# STM32F767xx register map
File version: 1.0
Registers are 32-bit, read-write, reset 0x0 unless marked. A register's access mark holds for its fields unless they carry their own. Offsets are from the block's base; [hi:lo] are bit positions; {n}, {i} and the like mark numbered series.

## DMA1
Base 0x40026000
Same registers: DMA2 0x40026400
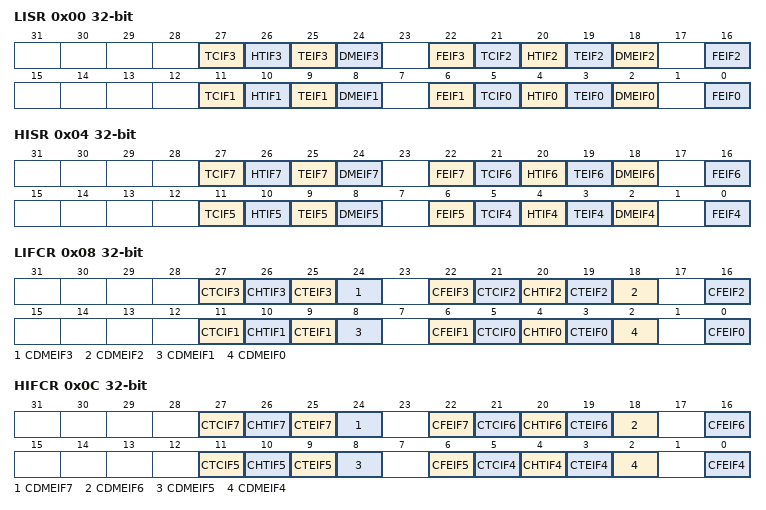
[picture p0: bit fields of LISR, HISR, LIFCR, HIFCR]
0x00 LISR — DMA low interrupt status register
  [27] TCIF3, [26] HTIF3, [25] TEIF3, [24] DMEIF3, [22] FEIF3, [21] TCIF2, [20] HTIF2, [19] TEIF2, [18] DMEIF2, [16] FEIF2, [11] TCIF1, [10] HTIF1, [9] TEIF1, [8] DMEIF1, [6] FEIF1, [5] TCIF0, [4] HTIF0, [3] TEIF0, [2] DMEIF0, [0] FEIF0
0x04 HISR — DMA high interrupt status register
  [27] TCIF7, [26] HTIF7, [25] TEIF7, [24] DMEIF7, [22] FEIF7, [21] TCIF6, [20] HTIF6, [19] TEIF6, [18] DMEIF6, [16] FEIF6, [11] TCIF5, [10] HTIF5, [9] TEIF5, [8] DMEIF5, [6] FEIF5, [5] TCIF4, [4] HTIF4, [3] TEIF4, [2] DMEIF4, [0] FEIF4
0x08 LIFCR — DMA low interrupt flag clear register
  [27] CTCIF3, [26] CHTIF3, [25] CTEIF3, [24] CDMEIF3, [22] CFEIF3, [21] CTCIF2, [20] CHTIF2, [19] CTEIF2, [18] CDMEIF2, [16] CFEIF2, [11] CTCIF1, [10] CHTIF1, [9] CTEIF1, [8] CDMEIF1, [6] CFEIF1, [5] CTCIF0, [4] CHTIF0, [3] CTEIF0, [2] CDMEIF0, [0] CFEIF0
0x0C HIFCR — DMA high interrupt flag clear register
  [27] CTCIF7, [26] CHTIF7, [25] CTEIF7, [24] CDMEIF7, [22] CFEIF7, [21] CTCIF6, [20] CHTIF6, [19] CTEIF6, [18] CDMEIF6, [16] CFEIF6, [11] CTCIF5, [10] CHTIF5, [9] CTEIF5, [8] CDMEIF5, [6] CFEIF5, [5] CTCIF4, [4] CHTIF4, [3] CTEIF4, [2] CDMEIF4, [0] CFEIF4
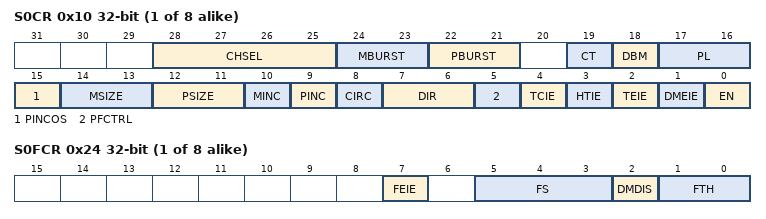
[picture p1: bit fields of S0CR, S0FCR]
{0x10+0x18*i} S{i}CR (i=0..7) — DMA stream x configuration register
  [28:25] CHSEL, [24:23] MBURST, [22:21] PBURST, [19] CT, [18] DBM, [17:16] PL, [15] PINCOS, [14:13] MSIZE, [12:11] PSIZE, [10] MINC, [9] PINC, [8] CIRC, [7:6] DIR, [5] PFCTRL, [4] TCIE, [3] HTIE, [2] TEIE, [1] DMEIE, [0] EN
{0x14+0x18*i} S{i}NDTR (i=0..7) — DMA stream x number of data register
  [15:0] SxNDT
{0x18+0x18*i} S{i}PAR (i=0..7) — DMA stream x peripheral address register
  [31:0] PA — Peripheral Address
{0x1C+0x18*i} S{i}M0AR (i=0..7) — DMA stream x memory 0 address register
  [31:0] M0A — Memory Address
{0x20+0x18*i} S{i}M1AR (i=0..7) — DMA stream x memory 1 address register
  [31:0] M1A — Memory Address
{0x24+0x18*i} S{i}FCR (i=0..7) — DMA stream x FIFO control register
  [7] FEIE, [5:3] FS, [2] DMDIS, [1:0] FTH

## ETH — Ethernet MAC
Base 0x40028000
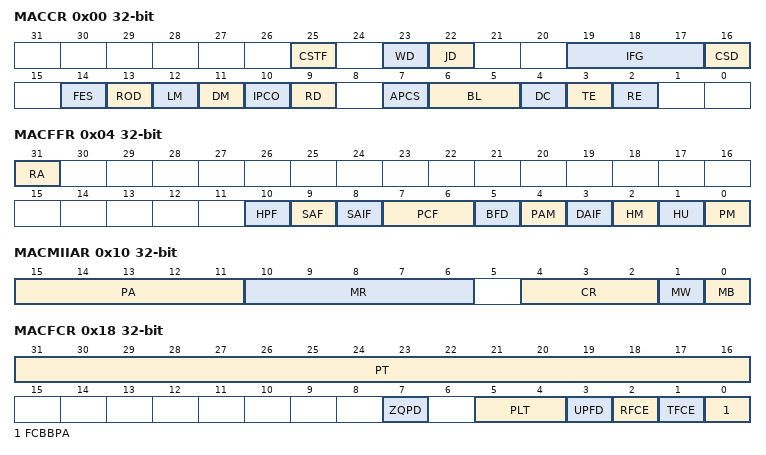
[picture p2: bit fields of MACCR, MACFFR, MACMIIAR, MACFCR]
0x00 MACCR
  [25] CSTF, [23] WD, [22] JD, [19:17] IFG, [16] CSD, [14] FES, [13] ROD, [12] LM, [11] DM, [10] IPCO, [9] RD, [7] APCS, [6:5] BL, [4] DC, [3] TE, [2] RE
0x04 MACFFR
  [31] RA, [10] HPF, [9] SAF, [8] SAIF, [7:6] PCF, [5] BFD, [4] PAM, [3] DAIF, [2] HM, [1] HU, [0] PM
0x08 MACHTHR
  [31:0] HTH
0x0C MACHTLR
  [31:0] HTL
0x10 MACMIIAR
  [15:11] PA, [10:6] MR, [4:2] CR, [1] MW, [0] MB
0x14 MACMIIDR
  [15:0] MD
0x18 MACFCR
  [31:16] PT, [7] ZQPD, [5:4] PLT, [3] UPFD, [2] RFCE, [1] TFCE, [0] FCBBPA
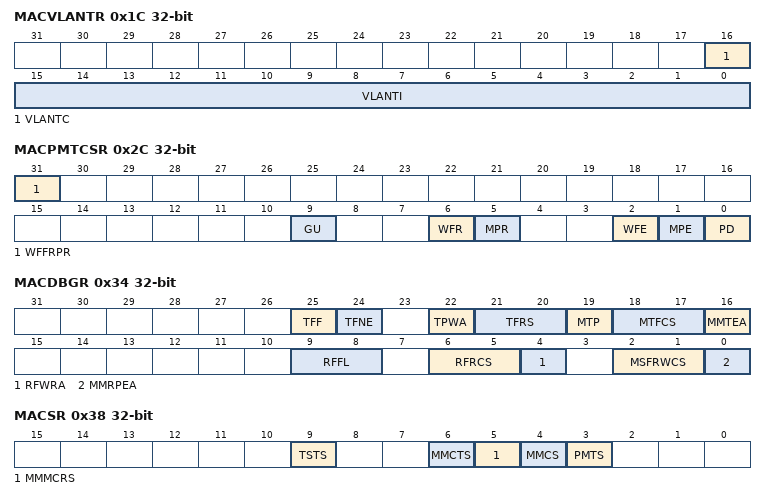
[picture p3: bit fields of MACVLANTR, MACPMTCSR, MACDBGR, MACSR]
0x1C MACVLANTR
  [16] VLANTC, [15:0] VLANTI
0x28 MACRWUFFR
  [31:0] D
0x2C MACPMTCSR
  [31] WFFRPR, [9] GU, [6] WFR, [5] MPR, [2] WFE, [1] MPE, [0] PD
0x34 MACDBGR
  [25] TFF, [24] TFNE, [22] TPWA, [21:20] TFRS, [19] MTP, [18:17] MTFCS, [16] MMTEA, [9:8] RFFL, [6:5] RFRCS, [4] RFWRA, [2:1] MSFRWCS, [0] MMRPEA
0x38 MACSR
  [9] TSTS, [6] MMCTS, [5] MMMCRS, [4] MMCS, [3] PMTS
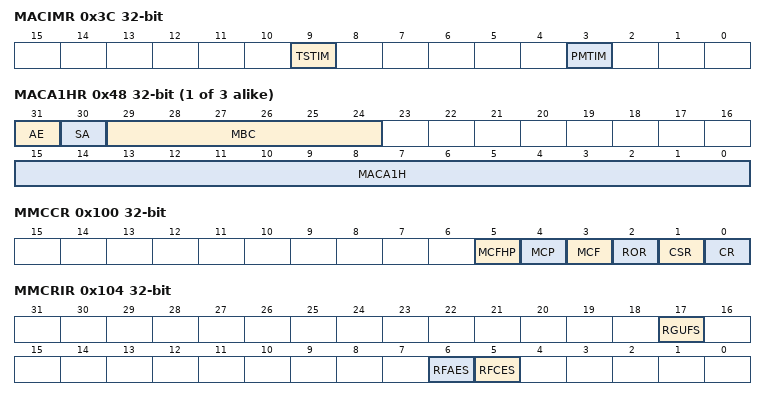
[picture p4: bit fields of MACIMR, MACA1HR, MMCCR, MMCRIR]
0x3C MACIMR
  [9] TSTIM, [3] PMTIM
0x40 MACA0HR
  [15:0] MACA0H
{0x44+8i} MACA{i}LR (i=0..3)
  [31:0] MACA{i}L
{0x40+8i} MACA{i}HR (i=1..3)
  [31] AE, [30] SA, [29:24] MBC, [15:0] MACA{i}H
0x100 MMCCR
  [5] MCFHP, [4] MCP, [3] MCF, [2] ROR, [1] CSR, [0] CR
0x104 MMCRIR
  [17] RGUFS, [6] RFAES, [5] RFCES
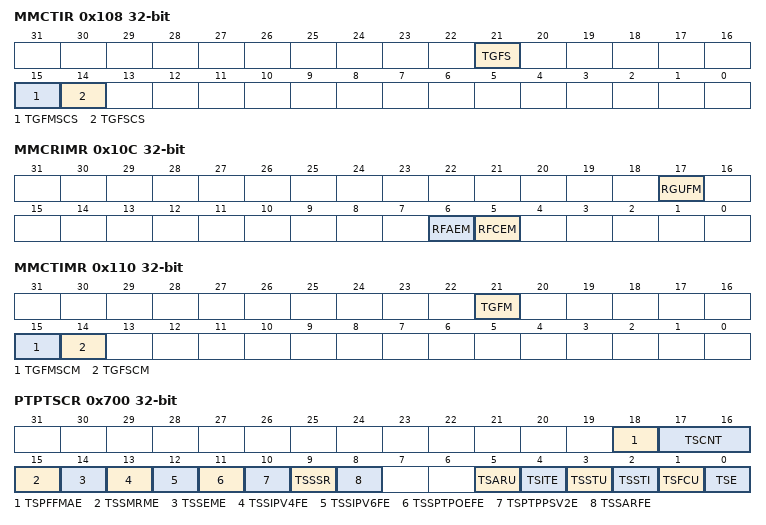
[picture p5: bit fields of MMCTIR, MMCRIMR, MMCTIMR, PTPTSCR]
0x108 MMCTIR
  [21] TGFS, [15] TGFMSCS, [14] TGFSCS
0x10C MMCRIMR
  [17] RGUFM, [6] RFAEM, [5] RFCEM
0x110 MMCTIMR
  [21] TGFM, [15] TGFMSCM, [14] TGFSCM
0x14C MMCTGFSCCR
  [31:0] TGFSCC
0x150 MMCTGFMSCCR
  [31:0] TGFMSCC
0x168 MMCTGFCR
  [31:0] TGFC
0x194 MMCRFCECR
  [31:0] RFCEC
0x198 MMCRFAECR
  [31:0] RFAEC
0x1C4 MMCRGUFCR
  [31:0] RGUFC
0x700 PTPTSCR
  [18] TSPFFMAE, [17:16] TSCNT, [15] TSSMRME, [14] TSSEME, [13] TSSIPV4FE, [12] TSSIPV6FE, [11] TSSPTPOEFE, [10] TSPTPPSV2E, [9] TSSSR, [8] TSSARFE, [5] TSARU, [4] TSITE, [3] TSSTU, [2] TSSTI, [1] TSFCU, [0] TSE
0x704 PTPSSIR
  [7:0] STSSI
0x708 PTPTSHR
  [31:0] STS
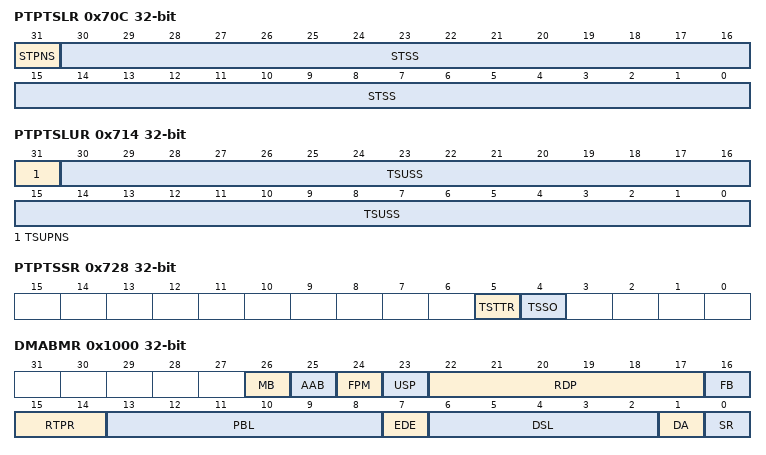
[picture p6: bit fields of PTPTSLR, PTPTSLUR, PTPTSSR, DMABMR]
0x70C PTPTSLR
  [31] STPNS, [30:0] STSS
0x710 PTPTSHUR
  [31:0] TSUS
0x714 PTPTSLUR
  [31] TSUPNS, [30:0] TSUSS
0x718 PTPTSAR
  [31:0] TSA
0x71C PTPTTHR
  [31:0] TTSH
0x720 PTPTTLR
  [31:0] TTSL
0x728 PTPTSSR
  [5] TSTTR, [4] TSSO
0x72C PTPPPSCR
  [3:0] PPSFREQ
0x1000 DMABMR
  [26] MB, [25] AAB, [24] FPM, [23] USP, [22:17] RDP, [16] FB, [15:14] RTPR, [13:8] PBL, [7] EDE, [6:2] DSL, [1] DA, [0] SR
0x1004 DMATPDR
  [31:0] TPD
0x1008 DMARPDR
  [31:0] RPD
0x100C DMARDLAR
  [31:0] SRL
0x1010 DMATDLAR
  [31:0] STL
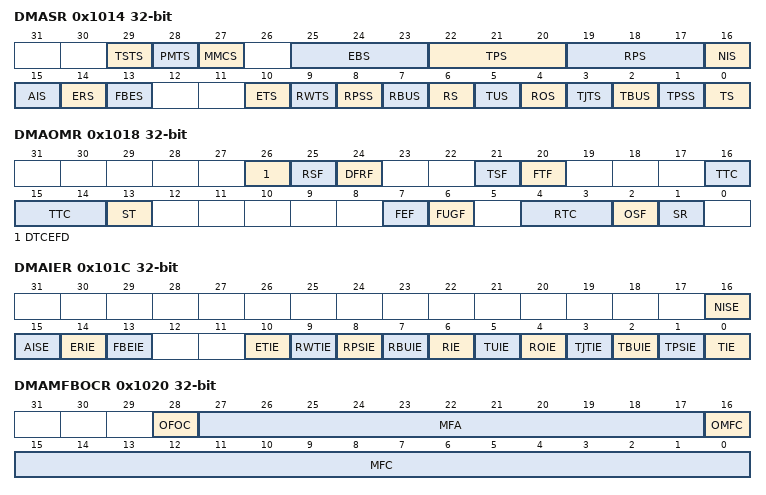
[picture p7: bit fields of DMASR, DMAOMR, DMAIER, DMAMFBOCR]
0x1014 DMASR
  [29] TSTS, [28] PMTS, [27] MMCS, [25:23] EBS, [22:20] TPS, [19:17] RPS, [16] NIS, [15] AIS, [14] ERS, [13] FBES, [10] ETS, [9] RWTS, [8] RPSS, [7] RBUS, [6] RS, [5] TUS, [4] ROS, [3] TJTS, [2] TBUS, [1] TPSS, [0] TS
0x1018 DMAOMR
  [26] DTCEFD, [25] RSF, [24] DFRF, [21] TSF, [20] FTF, [16:14] TTC, [13] ST, [7] FEF, [6] FUGF, [4:3] RTC, [2] OSF, [1] SR
0x101C DMAIER
  [16] NISE, [15] AISE, [14] ERIE, [13] FBEIE, [10] ETIE, [9] RWTIE, [8] RPSIE, [7] RBUIE, [6] RIE, [5] TUIE, [4] ROIE, [3] TJTIE, [2] TBUIE, [1] TPSIE, [0] TIE
0x1020 DMAMFBOCR
  [28] OFOC, [27:17] MFA, [16] OMFC, [15:0] MFC
0x1024 DMARSWTR
0x1048 DMACHTDR
  [31:0] HTDAP
0x104C DMACHRDR
  [31:0] HRDAP
0x1050 DMACHTBAR
  [31:0] HTBAP
0x1054 DMACHRBAR
  [31:0] HRBAP
